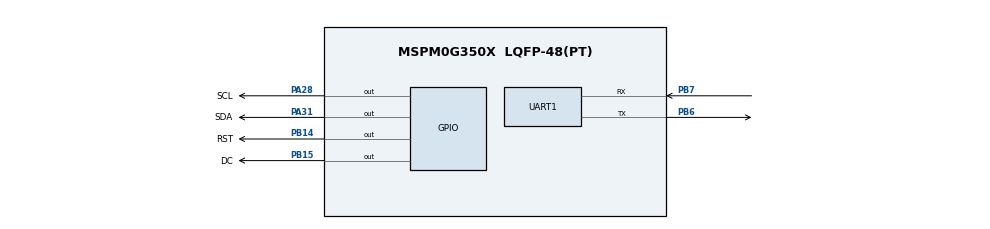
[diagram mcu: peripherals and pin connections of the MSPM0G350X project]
/**
 *
 * @cliArgs --device "MSPM0G350X" --part "Default" --package "LQFP-48(PT)" --product "mspm0_sdk@2.10.00.04"
 * @versions {"tool":"1.28.0+4696"}
 */

/**
 * Import the modules used in this configuration.
 */
const GPIO   = scripting.addModule("/ti/driverlib/GPIO", {}, false);
const GPIO1  = GPIO.addInstance();
const GPIO2  = GPIO.addInstance();
const GPIO3  = GPIO.addInstance();
const GPIO4  = GPIO.addInstance();
const SYSCTL = scripting.addModule("/ti/driverlib/SYSCTL");
const UART   = scripting.addModule("/ti/driverlib/UART", {}, false);
const UART1  = UART.addInstance();

/**
 * Write custom configuration values to the imported modules.
 */
GPIO1.$name                          = "OLED_RST";
GPIO1.associatedPins[0].$name        = "RST";
GPIO1.associatedPins[0].initialValue = "SET";
GPIO1.associatedPins[0].pin.$assign  = "PB14";

const Board = scripting.addModule("/ti/driverlib/Board", {}, false);

GPIO2.$name                          = "OLED_DC";
GPIO2.associatedPins[0].$name        = "DC";
GPIO2.associatedPins[0].initialValue = "SET";
GPIO2.associatedPins[0].pin.$assign  = "PB15";

GPIO3.$name                          = "OLED_SCL";
GPIO3.associatedPins[0].$name        = "SCL";
GPIO3.associatedPins[0].initialValue = "SET";
GPIO3.associatedPins[0].pin.$assign  = "PA28";

GPIO4.$name                          = "OLED_SDA";
GPIO4.associatedPins[0].$name        = "SDA";
GPIO4.associatedPins[0].initialValue = "SET";
GPIO4.associatedPins[0].pin.$assign  = "PA31";

SYSCTL.forceDefaultClkConfig = true;

UART1.$name                            = "UART_K230";
UART1.targetBaudRate                   = 115200;
UART1.enableFIFO                       = true;
UART1.enabledInterrupts                = ["RX"];
UART1.rxFifoThreshold                  = "DL_UART_RX_FIFO_LEVEL_ONE_ENTRY";
UART1.peripheral.$assign               = "UART1";
UART1.peripheral.rxPin.$assign         = "PB7";
UART1.peripheral.txPin.$assign         = "PB6";
UART1.txPinConfig.$name                = "ti_driverlib_gpio_GPIOPinGeneric0";
UART1.txPinConfig.direction            = scripting.forceWrite("OUTPUT");
UART1.txPinConfig.hideOutputInversion  = scripting.forceWrite(false);
UART1.txPinConfig.onlyInternalResistor = scripting.forceWrite(false);
UART1.txPinConfig.passedPeripheralType = scripting.forceWrite("Digital");
UART1.rxPinConfig.$name                = "ti_driverlib_gpio_GPIOPinGeneric1";
UART1.rxPinConfig.hideOutputInversion  = scripting.forceWrite(false);
UART1.rxPinConfig.onlyInternalResistor = scripting.forceWrite(false);
UART1.rxPinConfig.passedPeripheralType = scripting.forceWrite("Digital");
UART1.rxPinConfig.enableConfig         = true;
UART1.rxPinConfig.internalResistor     = "PULL_UP";

const ProjectConfig              = scripting.addModule("/ti/project_config/ProjectConfig", {}, false);
ProjectConfig.migrationCondition = true;

/**
 * Pinmux solution for unlocked pins/peripherals. This ensures that minor changes to the automatic solver in a future
 * version of the tool will not impact the pinmux you originally saw.  These lines can be completely deleted in order to
 * re-solve from scratch.
 */
Board.peripheral.$suggestSolution          = "DEBUGSS";
Board.peripheral.swclkPin.$suggestSolution = "PA20";
Board.peripheral.swdioPin.$suggestSolution = "PA19";
SYSCTL.peripheral.$suggestSolution         = "SYSCTL";
